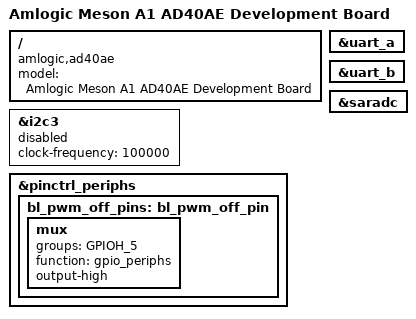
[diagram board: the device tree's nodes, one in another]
// SPDX-License-Identifier: (GPL-2.0+ OR MIT)
/*
 * Copyright (c) 2019 Amlogic, Inc. All rights reserved.
 */

/dts-v1/;

#include "meson-a1-a113l-ad40ae.dtsi"
#include "meson-a1_skt-panel.dtsi"

/ {
	compatible = "amlogic,ad40ae", "amlogic,a113l", "amlogic,meson-a1";
	model = "Amlogic Meson A1 AD40AE Development Board";
};

/* This UART is brought out to the DB9 connector */
&uart_a {
	status = "okay";
};

&uart_b {
	status = "okay";
};

&saradc {
	status = "okay";
};

/* demo for i2c user */
&i2c3 {
	status= "disabled";
	clock-frequency = <100000>;
	/* pinctrl-names = "default";*/
	/* pinctrl-0 = <&i2c3_master_pins2>;*/
};

&pinctrl_periphs {
	bl_pwm_off_pins:bl_pwm_off_pin {
		mux {
			groups = "GPIOH_5";
			function = "gpio_periphs";
			output-high;
		};
	};
}; /* end of pinctrl_periphs */
